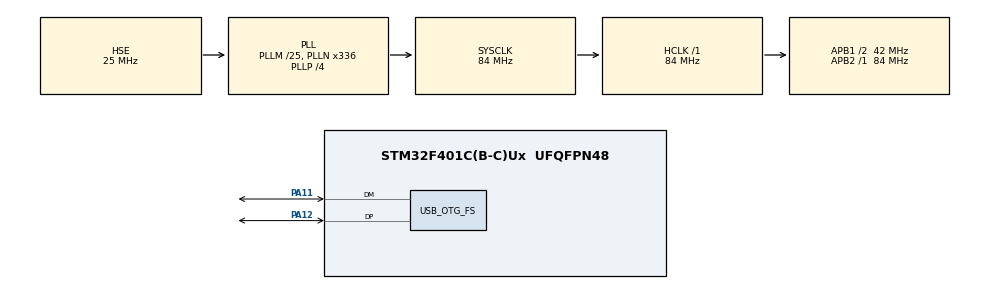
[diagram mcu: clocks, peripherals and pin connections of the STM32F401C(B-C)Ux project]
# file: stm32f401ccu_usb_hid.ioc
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Mcu.Family=STM32F4
Mcu.Name=STM32F401C(B-C)Ux
Mcu.Package=UFQFPN48
NVIC.OTG_FS_IRQn=true\:0\:0\:false\:false\:true\:false\:true
NVIC.PriorityGroup=NVIC_PRIORITYGROUP_4
PA11.Mode=Device_Only
PA11.Signal=USB_OTG_FS_DM
PA12.Mode=Device_Only
PA12.Signal=USB_OTG_FS_DP
PA13.Mode=Serial_Wire
PA13.Signal=SYS_JTMS-SWDIO
PA14.Mode=Serial_Wire
PA14.Signal=SYS_JTCK-SWCLK
PC14-OSC32_IN.Mode=LSE-External-Oscillator
PC14-OSC32_IN.Signal=RCC_OSC32_IN
PC15-OSC32_OUT.Mode=LSE-External-Oscillator
PC15-OSC32_OUT.Signal=RCC_OSC32_OUT
PH0\ -\ OSC_IN.Mode=HSE-External-Oscillator
PH0\ -\ OSC_IN.Signal=RCC_OSC_IN
PH1\ -\ OSC_OUT.Mode=HSE-External-Oscillator
PH1\ -\ OSC_OUT.Signal=RCC_OSC_OUT
ProjectManager.HeapSize=0x400
ProjectManager.StackSize=0x800
ProjectManager.TargetToolchain=TrueSTUDIO
RCC.48MHZClocksFreq_Value=48000000
RCC.AHBFreq_Value=84000000
RCC.APB1CLKDivider=RCC_HCLK_DIV2
RCC.APB1Freq_Value=42000000
RCC.APB1TimFreq_Value=84000000
RCC.APB2Freq_Value=84000000
RCC.APB2TimFreq_Value=84000000
RCC.CortexFreq_Value=84000000
RCC.HCLKFreq_Value=84000000
RCC.HSE_VALUE=25000000
RCC.HSI_VALUE=16000000
RCC.PLLM=25
RCC.PLLN=336
RCC.PLLP=RCC_PLLP_DIV4
RCC.PLLQ=7
RCC.SYSCLKFreq_VALUE=84000000
RCC.SYSCLKSource=RCC_SYSCLKSOURCE_PLLCLK
RCC.VCOOutputFreq_Value=336000000
USB_DEVICE.CLASS_NAME_FS=CUSTOM_HID
USB_DEVICE.MANUFACTURER_STRING=NEWTON FOUNDATION
USB_DEVICE.PRODUCT_STRING_CUSTOMHID_FS=NewKeyHID
USB_DEVICE.USBD_CUSTOMHID_OUTREPORT_BUF_SIZE=64
USB_DEVICE.USBD_CUSTOM_HID_REPORT_DESC_SIZE=34
USB_DEVICE.VirtualMode=CustomHid
USB_DEVICE.VirtualModeFS=Custom_Hid_FS
USB_OTG_FS.VirtualMode=Device_Only
VP_USB_DEVICE_VS_USB_DEVICE_CUSTOM_HID_FS.Mode=CUSTOM_HID_FS
board=custom

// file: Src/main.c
/* USER CODE BEGIN Header */
/**
  ******************************************************************************
  * @file           : main.c
  * @brief          : Main program body
  ******************************************************************************
  * @attention
  *
  * <h2><center>&copy; Copyright (c) 2019 STMicroelectronics.
  * All rights reserved.</center></h2>
  *
  * This software component is licensed by ST under Ultimate Liberty license
  * SLA0044, the "License"; You may not use this file except in compliance with
  * the License. You may obtain a copy of the License at:
  *                             www.st.com/SLA0044
  *
  ******************************************************************************
  */
/* USER CODE END Header */

#include "main.h"
#include "usb_device.h"
#include "gpio.h"

/* USER CODE BEGIN Includes */
#include "usbd_custom_hid_if.h"
#include "misc_utils.h"
/* USER CODE END Includes */

/* USER CODE BEGIN PTD */
uint8_t USB_RX_Buffer[USBD_CUSTOMHID_OUTREPORT_BUF_SIZE];
uint8_t USB_TX_Buffer[USBD_CUSTOMHID_OUTREPORT_BUF_SIZE];
extern USBD_HandleTypeDef hUsbDeviceFS;
/* USER CODE END PTD */

void SystemClock_Config(void);

/* USER CODE BEGIN 0 */
void usb_hid_process_input_data(uint8_t *data) {
	memcpy(USB_RX_Buffer,data,sizeof(USB_RX_Buffer));
	printf("receive: %s\n",(const char*)USB_RX_Buffer);
}
/* USER CODE END 0 */

int main(void)
{

  /* MCU Configuration--------------------------------------------------------*/

  /* Reset of all peripherals, Initializes the Flash interface and the Systick. */
  HAL_Init();

  /* Configure the system clock */
  SystemClock_Config();

  /* Initialize all configured peripherals */
  MX_GPIO_Init();
  MX_USB_DEVICE_Init();

  /* Infinite loop */
  while (1)
  {

    /* USER CODE BEGIN 3 */
		static uint32_t number = 0;
		number++;
		memset(USB_TX_Buffer,0,sizeof(USB_TX_Buffer));
		sprintf((char *) USB_TX_Buffer, "Hello from STM32: %lu", number);
		//USB_TX_Buffer[0] = 0x00;
		printf("send report: %s\n",(char *) USB_TX_Buffer);
		USBD_CUSTOM_HID_SendReport(&hUsbDeviceFS, USB_TX_Buffer,
				sizeof(USB_TX_Buffer)); // To send usb buffer to PC
		HAL_Delay(50);
  }
  /* USER CODE END 3 */
}

void SystemClock_Config(void)
{
  RCC_OscInitTypeDef RCC_OscInitStruct = {0};
  RCC_ClkInitTypeDef RCC_ClkInitStruct = {0};

  /** Configure the main internal regulator output voltage
  */
  __HAL_RCC_PWR_CLK_ENABLE();
  __HAL_PWR_VOLTAGESCALING_CONFIG(PWR_REGULATOR_VOLTAGE_SCALE2);
  /** Initializes the CPU, AHB and APB busses clocks
  */
  RCC_OscInitStruct.OscillatorType = RCC_OSCILLATORTYPE_HSE;
  RCC_OscInitStruct.HSEState = RCC_HSE_ON;
  RCC_OscInitStruct.PLL.PLLState = RCC_PLL_ON;
  RCC_OscInitStruct.PLL.PLLSource = RCC_PLLSOURCE_HSE;
  RCC_OscInitStruct.PLL.PLLM = 25;
  RCC_OscInitStruct.PLL.PLLN = 336;
  RCC_OscInitStruct.PLL.PLLP = RCC_PLLP_DIV4;
  RCC_OscInitStruct.PLL.PLLQ = 7;
  if (HAL_RCC_OscConfig(&RCC_OscInitStruct) != HAL_OK)
  {
    Error_Handler();
  }
  /** Initializes the CPU, AHB and APB busses clocks
  */
  RCC_ClkInitStruct.ClockType = RCC_CLOCKTYPE_HCLK|RCC_CLOCKTYPE_SYSCLK
                              |RCC_CLOCKTYPE_PCLK1|RCC_CLOCKTYPE_PCLK2;
  RCC_ClkInitStruct.SYSCLKSource = RCC_SYSCLKSOURCE_PLLCLK;
  RCC_ClkInitStruct.AHBCLKDivider = RCC_SYSCLK_DIV1;
  RCC_ClkInitStruct.APB1CLKDivider = RCC_HCLK_DIV2;
  RCC_ClkInitStruct.APB2CLKDivider = RCC_HCLK_DIV1;

  if (HAL_RCC_ClockConfig(&RCC_ClkInitStruct, FLASH_LATENCY_2) != HAL_OK)
  {
    Error_Handler();
  }
}

void Error_Handler(void)
{
}

/************************ (C) COPYRIGHT STMicroelectronics *****END OF FILE****/
